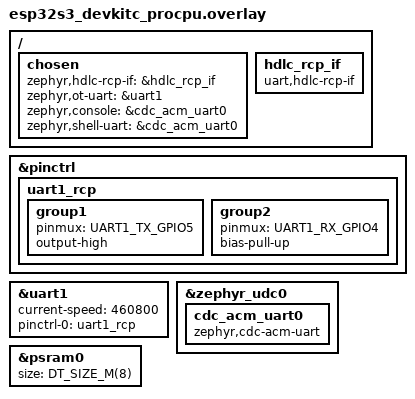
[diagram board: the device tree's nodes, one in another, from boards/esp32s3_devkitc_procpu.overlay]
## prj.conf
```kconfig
# Based on $ZEPHYR_BASE/samples/net/openthread/border_router (prj.conf +
# overlay-ot-rcp-host-wifi-esp.conf).

CONFIG_CPP=y
CONFIG_EVENTS=y

# Native ESP32-S3 USB console.  The new device stack uses the Espressif DWC2
# glue that allocates a valid Xtensa CPU interrupt for the USB OTG source.
# CDC is initialized and enabled before main(), so main only waits for DTR.
CONFIG_SERIAL=y
CONFIG_CONSOLE=y
CONFIG_UART_CONSOLE=y
CONFIG_STDOUT_CONSOLE=y
CONFIG_SHELL_BACKEND_SERIAL=y
CONFIG_UART_INTERRUPT_DRIVEN=y
CONFIG_UART_LINE_CTRL=y
CONFIG_USB_DEVICE_STACK_NEXT=y
CONFIG_CDC_ACM_SERIAL_INITIALIZE_AT_BOOT=y
CONFIG_CDC_ACM_SERIAL_ENABLE_AT_BOOT=y
CONFIG_CDC_ACM_SERIAL_PRODUCT_STRING="SoilSense Border Router"
CONFIG_CDC_ACM_SERIAL_PID=0x0004

# Networking: IPv6 + IPv4 on the Wi-Fi side (access network)
CONFIG_NETWORKING=y
CONFIG_NET_UDP=y
CONFIG_NET_TCP=y
CONFIG_NET_IPV6=y
CONFIG_NET_IPV4=y
CONFIG_NET_IPV4_MAPPING_TO_IPV6=y
CONFIG_NET_SOCKETS=y
CONFIG_NET_SOCKETS_INET_RAW=y
CONFIG_NET_DHCPV4=y
CONFIG_NET_MGMT_EVENT=y
CONFIG_NET_MGMT_EVENT_INFO=y
CONFIG_NET_MGMT_EVENT_STACK_SIZE=8192
CONFIG_NET_MGMT_EVENT_QUEUE_TIMEOUT=5000
CONFIG_NET_MGMT_EVENT_QUEUE_SIZE=16
CONFIG_NET_CONNECTION_MANAGER=y
CONFIG_NET_CONNECTION_MANAGER_MONITOR_STACK_SIZE=2048
CONFIG_NET_IPV6_ROUTE_MCAST=y
CONFIG_NET_IPV6_NBR_CACHE=y
CONFIG_NET_SOCKETS_SERVICE=y
CONFIG_NET_SOCKETS_SERVICE_STACK_SIZE=12288
CONFIG_NET_CONTEXT_RECV_PKTINFO=y
CONFIG_NET_CONTEXT_RECV_HOPLIMIT=y
CONFIG_NET_MAX_CONN=16
CONFIG_NET_MAX_CONTEXTS=15
CONFIG_ZVFS_POLL_MAX=16
CONFIG_ZVFS_OPEN_ADD_SIZE_NET_SAMPLE=16

CONFIG_NET_PKT_RX_COUNT=16
CONFIG_NET_PKT_TX_COUNT=16
CONFIG_NET_BUF_RX_COUNT=64
CONFIG_NET_BUF_TX_COUNT=64
CONFIG_NET_CONTEXT_NET_PKT_POOL=y

CONFIG_NET_IF_UNICAST_IPV6_ADDR_COUNT=6
CONFIG_NET_IF_MAX_IPV4_COUNT=2
CONFIG_NET_IF_MAX_IPV6_COUNT=6
# A Thread 1.2 Border Router must hold a 75-entry multicast listener table.
CONFIG_NET_IPV6_MAX_MCAST_ROUTES=85
CONFIG_NET_IF_MCAST_IPV6_ADDR_COUNT=85

CONFIG_DNS_RESOLVER=y
CONFIG_DNS_RESOLVER_PACKET_FORWARDING=y
CONFIG_DNS_RESOLVER_MAX_SERVERS=5
CONFIG_DNS_NUM_CONCUR_QUERIES=8
CONFIG_DNS_RESOLVER_MAX_NAME_LEN=128
CONFIG_DNS_RESOLVER_PRIVATE_RR_SUPPORT=y
CONFIG_DNS_RESOLVER_QUERY_ALL_AVAILABLE_SERVERS=y

# Wi-Fi
CONFIG_WIFI=y
CONFIG_WIFI_LOG_LEVEL_ERR=n
CONFIG_ETH_DRIVER=n

# OpenThread host; the 802.15.4 radio is the ESP32-C6 RCP on uart1
CONFIG_IEEE802154=n
CONFIG_HDLC_RCP_IF=y
CONFIG_NET_L2_OPENTHREAD=y
CONFIG_OPENTHREAD_THREAD_VERSION_1_4=y
CONFIG_OPENTHREAD_MANUAL_START=y
CONFIG_OPENTHREAD_RCP_RESTORATION_MAX_COUNT=10
CONFIG_OPENTHREAD_SETTINGS_RAM=y
CONFIG_OPENTHREAD_EXTERNAL_HEAP=y
CONFIG_OPENTHREAD_INTERFACE_EARLY_UP=y
CONFIG_OPENTHREAD_MAX_STATECHANGE_HANDLERS=3

# Border Router
CONFIG_OPENTHREAD_ZEPHYR_BORDER_ROUTER=y
CONFIG_OPENTHREAD_ZEPHYR_BORDER_ROUTER_BASE_SERVICE_NAME="SoilSense-BR"
CONFIG_OPENTHREAD_BORDER_ROUTER=y
CONFIG_OPENTHREAD_BORDER_ROUTING=y
CONFIG_OPENTHREAD_BORDER_ROUTING_COUNTERS=y
CONFIG_OPENTHREAD_BORDER_ROUTING_DHCP6_PD=y
CONFIG_OPENTHREAD_BORDER_ROUTING_DHCP6_PD_CLIENT=y
CONFIG_OPENTHREAD_BORDER_AGENT=y
CONFIG_OPENTHREAD_BORDER_AGENT_ID=y
CONFIG_OPENTHREAD_BORDER_AGENT_EPHEMERAL_KEY_ENABLE=y
CONFIG_OPENTHREAD_BORDER_AGENT_MESHCOP_SERVICE=y
CONFIG_OPENTHREAD_BACKBONE_ROUTER=y
CONFIG_OPENTHREAD_BACKBONE_ROUTER_MULTICAST_ROUTING=y
CONFIG_OPENTHREAD_NETDATA_PUBLISHER=y
CONFIG_OPENTHREAD_NAT64_TRANSLATOR=y
CONFIG_OPENTHREAD_SLAAC=y
CONFIG_OPENTHREAD_ENABLE_SERVICE=y
CONFIG_OPENTHREAD_DHCP6_CLIENT=y
CONFIG_OPENTHREAD_DHCP6_SERVER=y
CONFIG_OPENTHREAD_DNS_CLIENT=y
CONFIG_OPENTHREAD_DNS_CLIENT_OVER_TCP=y
CONFIG_OPENTHREAD_DNS_UPSTREAM_QUERY=y
CONFIG_OPENTHREAD_DNSSD_SERVER=y
CONFIG_OPENTHREAD_DNSSD_DISCOVERY_PROXY=y
CONFIG_OPENTHREAD_MULTICAST_DNS=y
CONFIG_OPENTHREAD_SRP_CLIENT=y
CONFIG_OPENTHREAD_SRP_SERVER=y
CONFIG_OPENTHREAD_SRP_ADV_PROXY=y
CONFIG_OPENTHREAD_TREL=y
CONFIG_OPENTHREAD_TREL_MANAGE_DNSSD=y
CONFIG_OPENTHREAD_DUA=y
CONFIG_OPENTHREAD_MLR=y
CONFIG_OPENTHREAD_TCP_ENABLE=y
CONFIG_OPENTHREAD_PLATFORM_UDP=y
CONFIG_OPENTHREAD_IP6_FRAGM=y
CONFIG_OPENTHREAD_ECDSA=y
CONFIG_OPENTHREAD_VERHOEFF_CHECKSUM=y
CONFIG_OPENTHREAD_JOINER=y
CONFIG_OPENTHREAD_COMMISSIONER=y
CONFIG_OPENTHREAD_COAP=y
CONFIG_OPENTHREAD_PING_SENDER=y
CONFIG_OPENTHREAD_MAC_FILTER=y
CONFIG_OPENTHREAD_LINK_METRICS_INITIATOR=y
CONFIG_OPENTHREAD_LINK_METRICS_SUBJECT=y
CONFIG_OPENTHREAD_LINK_METRICS_MANAGER=y
CONFIG_OPENTHREAD_NETDIAG_VENDOR_INFO=y
CONFIG_MBEDTLS_PSA_CRYPTO_LEGACY_RNG=y
CONFIG_ENTROPY_GENERATOR=y
CONFIG_TEST_RANDOM_GENERATOR=y

# Shell: "wifi ...", "net ..." and "ot ..."
CONFIG_SHELL=y
CONFIG_NET_SHELL=y
CONFIG_NET_L2_WIFI_SHELL=y
CONFIG_OPENTHREAD_SHELL=y
CONFIG_SHELL_GETOPT=y
CONFIG_SHELL_TAB=y
CONFIG_SHELL_TAB_AUTOCOMPLETION=y
CONFIG_SHELL_ARGC_MAX=26
CONFIG_SHELL_CMD_BUFF_SIZE=512
CONFIG_SHELL_BACKEND_SERIAL_RX_RING_BUFFER_SIZE=512

CONFIG_NVS=y

# Stacks
CONFIG_MAIN_STACK_SIZE=5120
# "ot dataset commit active" runs the Border Router callbacks on the shell
# thread; 5120 overflows.
CONFIG_SHELL_STACK_SIZE=8192
CONFIG_OPENTHREAD_THREAD_STACK_SIZE=8192
CONFIG_SYSTEM_WORKQUEUE_STACK_SIZE=4096
CONFIG_NET_TX_STACK_SIZE=4096
CONFIG_NET_RX_STACK_SIZE=4096
CONFIG_INIT_STACKS=y
CONFIG_STACK_SENTINEL=y

# Logging
CONFIG_LOG=y
CONFIG_LOG_PROCESS_THREAD=y
CONFIG_LOG_PROCESS_THREAD_STACK_SIZE=4096
CONFIG_NET_LOG=y
CONFIG_NET_STATISTICS=y
CONFIG_PRINTK=y
```

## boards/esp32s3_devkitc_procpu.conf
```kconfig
# ESP32-S3-DevKitC-1 N16R8: 8 MB octal PSRAM. OpenThread and the CLI live in
# PSRAM; internal DRAM is too small for them next to the Wi-Fi stack.
CONFIG_CONSOLE=y
CONFIG_SERIAL=y
CONFIG_UART_CONSOLE=y
CONFIG_SHELL_BACKEND_SERIAL=y

CONFIG_ESP_SPIRAM=y
CONFIG_SPIRAM_MODE_OCT=y
CONFIG_ESP_SPIRAM_HEAP_SIZE=524288
CONFIG_ESP_SPIRAM_BSS_RELOC_LIBS_AND_OBJS="libopenthread-ftd.a libopenthread-cli-ftd.a"

# Match the conservative 8 MB DTS flash map and flashing argument.
CONFIG_ESPTOOLPY_FLASHSIZE_8MB=y
```

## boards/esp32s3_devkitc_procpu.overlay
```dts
/* Spinel link to the ESP32-C6 RCP, crossed: S3 GPIO5 (TX) -> C6 GPIO4 (RX),
 * S3 GPIO4 (RX) <- C6 GPIO5 (TX), plus GND.
 */
/ {
	chosen {
		zephyr,hdlc-rcp-if = &hdlc_rcp_if;
		zephyr,ot-uart = &uart1;
		/* User console/shell: native ESP32-S3 USB, not CH343/UART0. */
		zephyr,console = &cdc_acm_uart0;
		zephyr,shell-uart = &cdc_acm_uart0;
	};

	hdlc_rcp_if: hdlc_rcp_if {
		compatible = "uart,hdlc-rcp-if";
	};
};

&pinctrl {
	uart1_rcp: uart1_rcp {
		group1 {
			pinmux = <UART1_TX_GPIO5>;
			output-high;
		};

		group2 {
			pinmux = <UART1_RX_GPIO4>;
			bias-pull-up;
		};
	};
};

&uart1 {
	status = "okay";
	current-speed = <460800>;
	pinctrl-0 = <&uart1_rcp>;
	pinctrl-names = "default";
};

/* Zephyr USB CDC-ACM UART emulation on the ESP32-S3 native USB peripheral. */
&zephyr_udc0 {
	status = "okay";

	cdc_acm_uart0: cdc_acm_uart0 {
		compatible = "zephyr,cdc-acm-uart";
	};
};

&psram0 {
	size = <DT_SIZE_M(8)>;
};
```

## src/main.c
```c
/* The Border Router starts by itself once Wi-Fi is up and the Thread network
 * is formed; everything in Lab 5 happens on the shell.
 *
 * Lab 8 builds with autostart.conf (CONFIG_LAB_AUTOSTART): the Thread network
 * and the Wi-Fi credentials stay in flash, and both are rejoined at boot, so a
 * power cut needs nobody at the console.
 */
#include <zephyr/kernel.h>
#include <zephyr/logging/log.h>
#include <zephyr/sys/printk.h>

#define LAB5_UART_BUILD_ID "LAB5-UART-STABLE-V2"

#if defined(CONFIG_LAB_AUTOSTART)
#include <zephyr/net/net_if.h>
#include <zephyr/net/net_mgmt.h>
#include <zephyr/net/wifi_credentials.h>
#include <zephyr/net/wifi_mgmt.h>
#include <openthread.h>
#include <openthread/dataset.h>

LOG_MODULE_REGISTER(lab5_border_router, LOG_LEVEL_INF);

static void autostart(void)
{
	struct net_if *wifi = net_if_get_first_wifi();
	bool stored;

	if (wifi != NULL && !wifi_credentials_is_empty()) {
		LOG_INF("Connecting to the stored Wi-Fi network");
		(void)net_mgmt(NET_REQUEST_WIFI_CONNECT_STORED, wifi, NULL, 0);
	} else {
		LOG_INF("No Wi-Fi network stored: add one with \"wifi cred add\"");
	}

	openthread_mutex_lock();
	stored = otDatasetIsCommissioned(openthread_get_default_instance());
	openthread_mutex_unlock();
	if (stored && openthread_run() == 0) {
		LOG_INF("Rejoining the stored Thread network");
	} else if (!stored) {
		LOG_INF("No Thread network stored: form one (SOP-05 §2)");
	}
}
#endif

int main(void)
{
	printk("\n[%s] main thread alive; console is UART0/CH343\n",
	       LAB5_UART_BUILD_ID);

#if defined(CONFIG_LAB_AUTOSTART)
	autostart();
#endif

	/* Never return from main.  Picolibc's _exit() prints "exit" and then
	 * spins forever; that starves the shell and makes a healthy UART console
	 * look as if the serial monitor closed by itself.
	 */
	for (;;) {
		k_sleep(K_SECONDS(60));
	}
}
```
